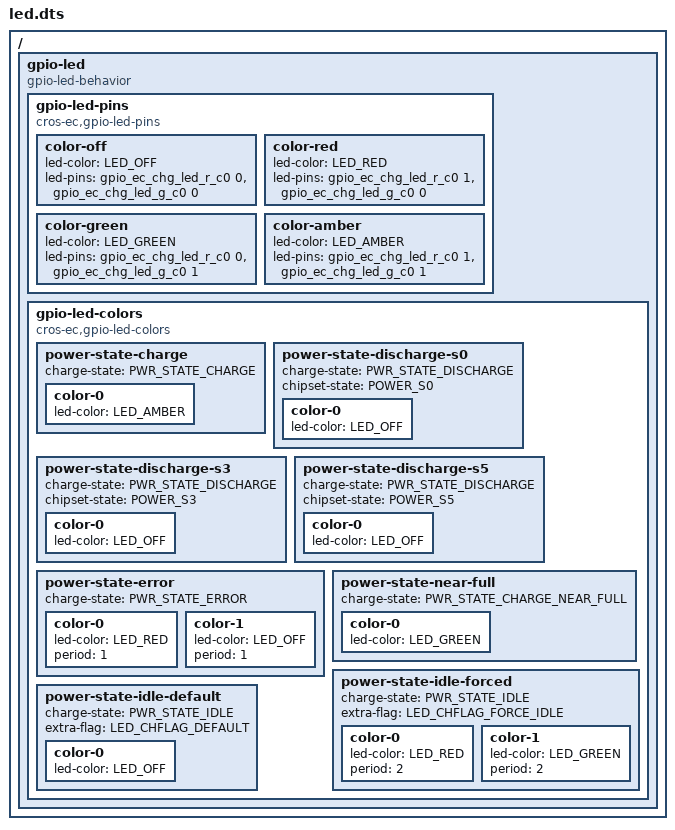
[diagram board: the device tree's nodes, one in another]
/ {
	gpio-led {
		compatible = "gpio-led-behavior";

		gpio-led-pins {
			compatible = "cros-ec,gpio-led-pins";

			color-off {
				led-color = "LED_OFF";
				led-pins = <&gpio_ec_chg_led_r_c0 0>,
					   <&gpio_ec_chg_led_g_c0 0>;
			};

			color-red {
				led-color = "LED_RED";
				led-pins = <&gpio_ec_chg_led_r_c0 1>,
					   <&gpio_ec_chg_led_g_c0 0>;
			};

			color-green {
				led-color = "LED_GREEN";
				led-pins = <&gpio_ec_chg_led_r_c0 0>,
					   <&gpio_ec_chg_led_g_c0 1>;
			};

			color-amber {
				led-color = "LED_AMBER";
				led-pins = <&gpio_ec_chg_led_r_c0 1>,
					   <&gpio_ec_chg_led_g_c0 1>;
			};
		};

		gpio-led-colors {
			compatible = "cros-ec,gpio-led-colors";

			power-state-charge {
				charge-state = "PWR_STATE_CHARGE";

				color-0 {
					led-color = "LED_AMBER";
				};
			};

			power-state-discharge-s0 {
				charge-state = "PWR_STATE_DISCHARGE";
				chipset-state = "POWER_S0";

				color-0 {
					led-color = "LED_OFF";
				};
			};

			power-state-discharge-s3 {
				charge-state = "PWR_STATE_DISCHARGE";
				chipset-state = "POWER_S3";

				color-0 {
					led-color = "LED_OFF";
				};
			};

			power-state-discharge-s5 {
				charge-state = "PWR_STATE_DISCHARGE";
				chipset-state = "POWER_S5";

				color-0 {
					led-color = "LED_OFF";
				};
			};

			power-state-error {
				charge-state = "PWR_STATE_ERROR";

				/* RED 1 sec, off 1 sec */
				color-0 {
					led-color = "LED_RED";
					period = <1>;
				};
				color-1 {
					led-color = "LED_OFF";
					period = <1>;
				};
			};

			power-state-near-full {
				charge-state = "PWR_STATE_CHARGE_NEAR_FULL";

				color-0 {
					led-color = "LED_GREEN";
				};
			};

			power-state-idle-forced {
				charge-state = "PWR_STATE_IDLE";
				extra-flag = "LED_CHFLAG_FORCE_IDLE";

				/* Red 2 sec, Amber 2 sec */
				color-0 {
					led-color = "LED_RED";
					period = <2>;
				};
				color-1 {
					led-color = "LED_GREEN";
					period = <2>;
				};
			};

			power-state-idle-default {
				charge-state = "PWR_STATE_IDLE";
				extra-flag = "LED_CHFLAG_DEFAULT";

				color-0 {
					led-color = "LED_OFF";
				};
			};
		};
	};
};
